# nrf7140_wificore register map
Vendor: Nordic Semiconductor; Series: nRF71; File version: 1
Registers are 32-bit, read-write, reset 0x0 unless marked. A register's access mark holds for its fields unless they carry their own. Offsets are from the block's base; [hi:lo] are bit positions; lines under a group give offsets from that group; 'fields as' and 'values as' point back to an identical list; <NAME> marks a mode.

## RPUPHY (part 1 of 8) — WIFICore RPU PHY peripherals
Base 0x48080000; alternate view of RPUMAC
0x7000 SCP group — Unspecified
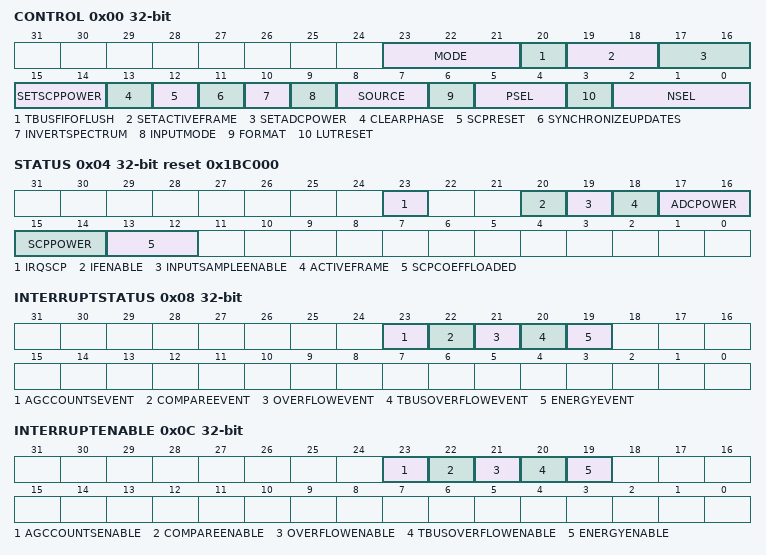
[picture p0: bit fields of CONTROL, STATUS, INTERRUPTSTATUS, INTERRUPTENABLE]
  0x00 CONTROL — SCP CONTROL
    [23:21] MODE — Defines the operating mode of the SCP as follows:0: Normal operation; SCP samples are output1: LO phase accumulator (MSB:MSB-11) is output on ILO phase accumulator(MSB-12:MSB-23) is output on Q2: Bypass mode 1; resampler results are output on I and Q3: Bypass mode 2; mixer results are output on I and Q4: Samples bypass the SCP completely
    [20] TBUSFIFOFLUSH — Writing '1' to this field causes the TBus output FIFO to be flushed.This bit clears automatically.
    [19:18] SETACTIVEFRAME
      0=NoChange; 1=NoChange1; 2=FrameAActive; 3=FrameBActive
    [17:16] SETADCPOWER
      0=NoChange; 1=LowPowerMode; 2=PowerOn; 3=PowerOff
    [15:14] SETSCPPOWER
      0=NoChange; 1=LowPowerMode; 2=PowerOn; 3=PowerOff
    [13] CLEARPHASE
      0=Resampler and LO phase accumulators run normally; 1=ResamplerAndLoPhaseA1 (Resampler and LO phase accumulators are forced to zero)
    [12] SCPRESET
      0=SCP signal path operates normally; 1=SCP signal path held in a reset state (clears CIC and notch phase accumulators)
    [11] SYNCHRONIZEUPDATES
      0=Updates to parameters take effect immediately; 1=Updates to parameters are synchronized to the APPLY_PARAMETERS sample count value
    [10] INVERTSPECTRUM — Note: The mixer design under normal operation inverts the output I and Q samples even if this field is set to 0. To re-invert set field to 1.
      0=The mixer output spectrum is not inverted; 1=TheMixerOutputSpectr1 (The mixer output spectrum is inverted by swapping I and Q)
    [9] INPUTMODE
      0=Input samples represent a real IF signal; 1=Input samples are I/Q pairs
    [8:7] SOURCE — Specifies the input IF sample source as follows:
      0=SourceIsOnBoardAdc; 1=SourceIsTbusWrPort; 2=SourceIsInputSample; 3=Reserve (This is reserved.)
    [6] FORMAT — Specifies the input IF sample format as follows:
      0=2SComplementSamples; 1=OffsetBinarySamples
    [5:4] PSEL — Defines the decimation ratio P of the final decimation stage of the SCP as follows:
      0=P2; 1=P3; 2=P1; 3=P4
    [3] LUTRESET — Writing '1' to this field causes the LUT select signals to be reset.This bit clears automatically.
    [2:0] NSEL — Defines the decimation ratio N of the first decimation stage of the SCP as follows:
      0=NoDecimation; 1=DecimateBy2; 2=DecimateBy3; 3=DecimateBy4; 4=DecimateBy6; 5=DecimateBy8; 6=DecimateBy12; 7=DecimateBy16
  0x04 STATUS ro reset 0x1BC000 — SCP STATUS
    [23] IRQSCP — This signal reflects the state of the IRQ_SCP interrupt.This interrupt is controlled by SCP_Interrupt_Enable.
    [20] IFENABLE
      0=Input synchroniser not enabled; 1=Input synchroniser enabled
    [19] INPUTSAMPLEENABLE
      0=SCP not ready for write to SCP_INPUT_SAMPLE register; 1=SCP ready for write to SCP_INPUT_SAMPLE register
    [18] ACTIVEFRAME
      0=FrameAActive; 1=FrameBActive
    [17:16] ADCPOWER
      0=Undefined; 1=LowPowerMode; 2=PowerOn; 3=PowerOff
    [15:14] SCPPOWER
      0=Undefined; 1=LowPowerMode; 2=PowerOn; 3=PowerOff
    [13:12] SCPCOEFFLOADED
      0=CoeffsAreNotLoaded; 2=CoeffsSet0IsLoaded; 3=CoeffsSet1IsLoaded
  0x08 INTERRUPTSTATUS — SCP INTERRUPT STATUS
    [23] AGCCOUNTSEVENT — This bit is set to 1 when the AGC period has completed.Writing 1 sets this bit for test purposes (and hence asserts the interrupt if AGC_COUNTS_ENABLE is also set).
    [22] COMPAREEVENT — This bit is set to 1 when the frame compare test has matched.Writing 1 sets this bit for test purposes (and hence asserts the interrupt if COMPARE_ENABLE is also set).
    [21] OVERFLOWEVENT — This bit is set to 1 when the input synchroniser has overflowed.Writing 1 sets this bit for test purposes (and hence asserts the interrupt if OVERFLOW_ENABLE is also set).
    [20] TBUSOVERFLOWEVENT — This bit is set to 1 if the TBus output FIFO overflows.Writing 1 sets this bit for test purposes (and hence asserts the interrupt if TBUS_OVERFLOW_ENABLE is also set).
    [19] ENERGYEVENT — This bit is set to 1 when Energy Monitor outputs are ready to be read.Writing 1 sets this bit for test purposes (and hence asserts the interrupt if ENERGY_ENABLE is also set).
  0x0C INTERRUPTENABLE — SCP INTERRUPT ENABLE
    [23] AGCCOUNTSENABLE — IRQ_SCP is asserted when AGC_COUNTS_EVENT=1 and AGC_COUNTS_ENABLE=1.
    [22] COMPAREENABLE — IRQ_SCP is asserted when COMPARE_EVENT=1 and COMPARE_ENABLE=1.
    [21] OVERFLOWENABLE — IRQ_SCP is asserted when OVERFLOW_EVENT=1 and OVERFLOW_ENABLE=1.
    [20] TBUSOVERFLOWENABLE — IRQ_SCP is asserted when TBUS_OVERFLOW_EVENT=1 and TBUS_OVERFLOW_ENABLE=1.
    [19] ENERGYENABLE — IRQ_SCP is asserted when ENERGY_EVENT=1 and ENERGY_ENABLE=1.
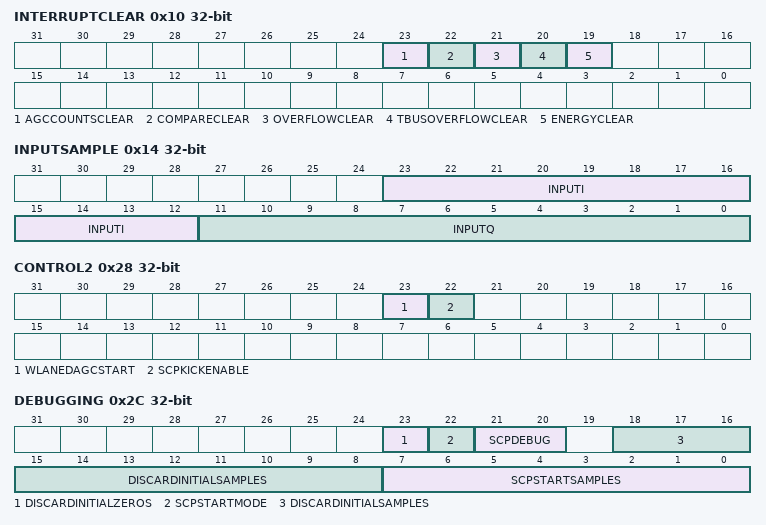
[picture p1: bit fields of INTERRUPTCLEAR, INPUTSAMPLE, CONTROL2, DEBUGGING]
  0x10 INTERRUPTCLEAR — SCP INTERRUPT CLEAR
    [23] AGCCOUNTSCLEAR — Writing 1 to this bit sets AGC_COUNTS_EVENT to 0.
    [22] COMPARECLEAR — Writing 1 to this bit sets COMPARE_EVENT to 0
    [21] OVERFLOWCLEAR — Writing 1 to this bit sets OVERFLOW_EVENT to 0
    [20] TBUSOVERFLOWCLEAR — Writing 1 to this bit sets TBUS_OVERFLOW_EVENT to 0
    [19] ENERGYCLEAR — Writing 1 to this bit sets ENERGY_EVENT to 0
  0x14 INPUTSAMPLE — SCP INPUT SAMPLE
    [23:12] INPUTI — For 12-bit SCP : write input sample I component.For 16-bit SCP : write input sample I[15:12] followed by Q[15:12].Poll for INPUT_SAMPLE_ENABLE=1 before writing.
    [11:0] INPUTQ — For 12-bit SCP : input sample Q component.For 16-bit SCP : write input sample I[11:0] followed by Q[11:0].Poll for INPUT_SAMPLE_ENABLE=1 before writing.
  0x18 REFERENCECLOCKCONTROLN — SCP REFERENCE CLOCK CONTROL N
    [23:8] N — The frequency of the output ref_clk is R x (N[14:0] / (M * 2)), where R is the SCP output sample frequency when N[15]=0, else the core clock frequency.If N and M are to be used to scale the reference clock M must be programmed first followed by N.Note that the reference clock control can only act as a divider not as a multiplier so the ratio (N[14:0] / (M * 2)) must be less than or equal to 0.5.
  0x1C REFERENCECLOCKCONTROLM — SCP REFERENCE CLOCK CONTROL M
    [23:8] M — The frequency of the output ref_clk is R x (N[14:0] / (M * 2)), where R is the SCP sample frequency when N[15]=0, else the core clock frequency.If N and M are to be used to scale the reference clock M must be programmed first followed by N.Note that the Reference clock control can only act as a divider not as a multiplier so the ratio (N[14:0] / (M * 2)) must be less than or equal to 0.5.
  0x20 CICBYPASS — SCP CIC BYPASS
    [23] CICBYPASS — Used to set the bypass mode of the CIC block.When bypass is set the CIC block is powered down and data passes around it unaltered.When cleared the block operates as programmed by the registers that control it.
      0=NormalOperation; 1=Block Bypassed (overrules any other block settings)
  0x24 RSSIINPUT — SCP RSSI INPUT
    [19:8] RSSIINPUT — RSSI (Received Signal Strength Indicator) ADC input captured on AGC sample period trigger
  0x28 CONTROL2 — SCP CONTROL2
    [23] WLANEDAGCSTART — Note: In mode 1 the input data rate to the SCP must be greater than or equal to the output data rate.
      0=SCP not used for processing Wi-Fi samples. No hold off provided to synchronize output samples with ADC input, DMA output enabled at start of frame.; 1=SCP used for processing Wi-Fi samples. Provides hold off to synchronize output samples with ADC input, DMA output enabled by agc_done signal from Wi-Fi AGC.
    [22] SCPKICKENABLE
      0=Writes to SET_ADC_POWER/SET_SCP_POWER/NEW_ADC_POWER/NEW_SCP_POWER/INPUT_I/INPUT_Q registers not deferred until kick received from EDC_SCP_KICK register to synchroniser update of these registers to multiple SCPs; 1=WritesToSetAdcPowe1 (Writes to SET_ADC_POWER/SET_SCP_POWER/NEW_ADC_POWER/NEW_SCP_POWER/INPUT_I/INPUT_Q registers deferred until kick received from EDC_SCP_KICK register to synchroniser update of these registers to multiple SCPs.)
  0x2C DEBUGGING — SCP DEBUG
    [23] DISCARDINITIALZEROS
      0=Process all ADC input samples; 1=Discard initial ADC input data until first non-zero sample
    [22] SCPSTARTMODE
      0=Output all SCP output samples, or all samples after ED event when WLAN_EDAGC_START=1; 1=Discard first SCP_START_SAMPLES SCP output samples
    [21:20] SCPDEBUG — Enable debug registers SCP_DEBUG_VALID and SCP_DEBUG_ENABLE
      0=Disabled; 1=ValidEnable; 2=Sticky(Valid), Sticky(Enable); 3=Valid & Enable, Sticky(Valid & Enable)
    [18:8] DISCARDINITIALSAMPLES — Number of initial ADC samples to discard
    [7:0] SCPSTARTSAMPLES — Number of samples before enabling SCP output when SCP_START_MODE=1
  0x30 DEBUGVALID0 ro — SCP DEBUG VALID 0
    [23:0] SCPDEBUGVALID0 — Live state of the valid flow control signals0: Source Synchroniser Output1: RI/Q Formatter Input2: RI/Q Formatter Output3: NDRM Decimator Input4: NDRM Decimator Output5: FDC Offset Input6: FDC Offset Output7: EEarly Gain Input8: EEarly Gain Output9: RMixer Input10: Mixer Output11: Resampler Input12: Resampler Output13: IQ Imbalance Input14: IQ Imbalance Output15: CIC Decimator Input16: CIC Decimator Output17: FIR Decimator Input18: FIR Decimator Output19: Notch Filter Input20: Notch Filter Output21: Late Gain Input22: Late Gain Output23: Impulse Filter Input
  0x34 DEBUGVALID1 ro — SCP DEBUG VALID 1
    [6:0] SCPDEBUGVALID1 — Live state of the valid flow control signals0: Impulse Filter Output1: Output Mux Input2: FIFO Write3: FIFO Output4: Unpacker Input5: EDC T-Bus Read Peripheral Input6: EDC T-Bus Read Peripheral Output
  0x38 DEBUGENABLE0 ro — SCP DEBUG ENABLE 0
    [23:0] SCPDEBUGENABLE0 — Live state of the valid flow control signals0: Source Synchroniser Output1: RI/Q Formatter Input2: RI/Q Formatter Output3: NDRM Decimator Input4: NDRM Decimator Output5: FDC Offset Input6: FDC Offset Output7: EEarly Gain Input8: EEarly Gain Output9: RMixer Input10: Mixer Output11: Resampler Input12: Resampler Output13: IQ Imbalance Input14: IQ Imbalance Output15: CIC Decimator Input16: CIC Decimator Output17: FIR Decimator Input18: FIR Decimator Output19: Notch Filter Input20: Notch Filter Output21: Late Gain Input22: Late Gain Output23: Impulse Filter Input
  0x3C DEBUGENABLE1 ro — SCP DEBUG ENABLE 1
    [6:0] SCPDEBUGENABLE1 — Live state of the valid flow control signals0: Impulse Filter Output1: Output Mux Input2: FIFO Full3: FIFO Output4: Unpacker Input5: EDC T-Bus Read Peripheral Input6: EDC T-Bus Read Peripheral Output
  0x40 COEFFADDR — SCP COEFF ADDR
    [5:0] SCPCOEFFADDR — Address for coefficient of final (FIR) decimation filter.NOTE: use FIR_COEFF_SET_SEL to select the coefficients set.
  0x44 COEFFDATA — SCP COEFF DATA
    [16:0] SCPCOEFFDATA — Data for coefficient of final (FIR) decimation filter in 2's complement format where the range of numbers represented is -1.0 to 1.0.SCP_COEFF_ADDR automatically increments following write.
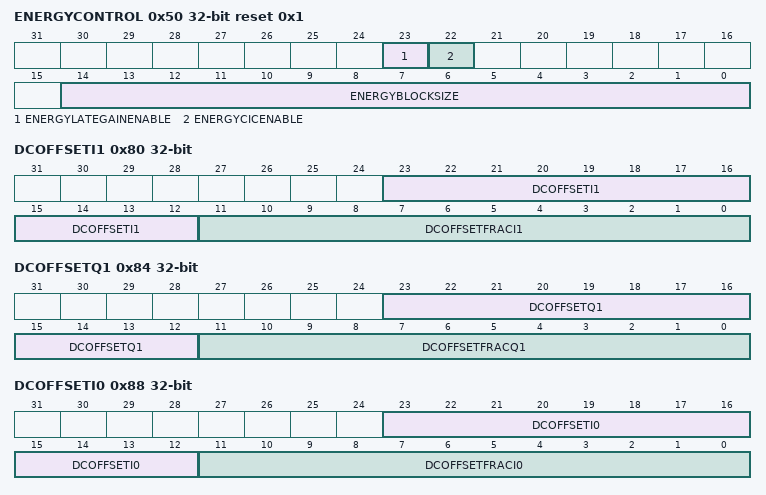
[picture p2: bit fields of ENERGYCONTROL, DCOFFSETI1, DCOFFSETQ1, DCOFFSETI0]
  0x50 ENERGYCONTROL reset 0x1 — SCP ENERGY CONTROL
    [23] ENERGYLATEGAINENABLE — Enable control for the energy calculation on the input of the late gain block:
      0=Energy calculation disabled; 1=Energy calculation enabled
    [22] ENERGYCICENABLE — Enable, disable the energy calculation on the input of the CIC decimator block.
      0=Energy calculation disabled; 1=Energy calculation enabled
    [14:0] ENERGYBLOCKSIZE — Block size for the energy calculation at the CIC decimator and the late gain stage, shifted right by 6.Takes values in the range [1 ~ 2^14] and must be a power of 2.
  0x54 ENERGYCICVALUE ro — SCP ENERGY CIC VALUE
    [23:0] ENERGYCICVALUE — Energy value from CIC decimator energy monitor block.
  0x58 ENERGYLATEGAINVALUE ro — SCP ENERGY LATE GAIN VALUE
    [23:0] ENERGYLATEGAINVALUE — Energy value from late gain energy monitor block.
  0x60 EARLYCOARSEGAIN — SCP EARLY COARSE GAIN
    [23:22] EARLYCOARSEGAIN — Coarse gain applied in the early gain block.
      0=CoarseGainOf1; 1=CoarseGainOf14; 2=CoarseGainOf4; 3=Reserve (This is reserved.)
  0x64 EARLYFINEGAINI reset 0x200000 — SCP EARLY FINE GAIN I
    [23:10] EARLYIGAIN — 2's complement value that multiplies I value from SCP.This is a linear gain where 0x800 represents the 0dB point, thus the fine gain is EARLY_I_GAIN/0x800.Bits 23:13 valid for 12-bit SCP, bits 23:10 valid for 16-bit SCP.
  0x68 EARLYFINEGAINQ reset 0x200000 — SCP EARLY FINE GAIN Q
    [23:10] EARLYQGAIN — 2's complement value that multiplies Q value from SCP.This is a linear gain where 0x800 represents the 0dB point, thus the fine gain is EARLY_Q_GAIN/0x800.Bits 23:13 valid for 12-bit SCP, bits 23:10 valid for 16-bit SCP.
  0x6C EARLYANGLEIQ — SCP EARLY ANGLE IQ
    [23:10] EARLYITOQGAIN — 2's complement value that multiplies I value before addition to Q value in the early gain block.Qout = Q + (I * EARLY_I_TO_Q_GAIN >> 13).Bits 23:13 valid for 12-bit SCP, bits 23:10 valid for 16-bit SCP.
  0x74 LATECOARSEGAIN — SCP LATE COARSE GAIN
    [23] LATECOARSEGAIN — Coarse gain applied in the late gain block.
      0=CoarseGainOf1; 1=CoarseGainOf4
  0x78 LATEFINEGAINI reset 0x200000 — SCP LATE FINE GAIN I
    [23:13] LATEIGAIN — 2's complement value that multiplies I value from SCP. This is a linear gain where 0x100 represents the 0dB point, thus the fine gain is LATE_I_GAIN/0x100.
  0x7C LATEFINEGAINQ reset 0x200000 — SCP LATE FINE GAIN Q
    [23:13] LATEQGAIN — 2's complement value that multiplies Q value from SCP. This is a linear gain where 0x100 represents the 0dB point, thus the fine gain is LATE_Q_GAIN/0x100.
  0x80 DCOFFSETI1 — SCP DC OFFSET I 1
    [23:12] DCOFFSETI1 — DC offset cancellation value for the real or I channel. 2's complement value, where the number of integer bits are defined by the I channel size and the remainder bits are fractional. The fractional bits enter a wrapping accumulator and the carry from this is summed with the integer offset.
    [11:0] DCOFFSETFRACI1 — DC offset cancellation value for the real or I channel. 2's complement value, where the number of integer bits are defined by the I channel size and the remainder bits are fractional. The fractional bits enter a wrapping accumulator and the carry from this is summed with the integer offset.
  0x84 DCOFFSETQ1 — SCP DC OFFSET Q 1
    [23:12] DCOFFSETQ1 — DC offset cancellation value for the Q channel. 2's complement value, where the number of integer bits are defined by the Q channel size and the remainder bits are fractional. The fractional bits enter a wrapping accumulator and the carry from this is summed with the integer offset.
    [11:0] DCOFFSETFRACQ1 — DC offset cancellation value for the Q channel. 2's complement value, where the number of integer bits are defined by the Q channel size and the remainder bits are fractional. The fractional bits enter a wrapping accumulator and the carry from this is summed with the integer offset.
  0x88 DCOFFSETI0 — SCP DC OFFSET I 0
    [23:12] DCOFFSETI0 — DC offset cancellation value for the real or I channel. 2's complement value, where the number of integer bits are defined by the I channel size and the remainder bits are fractional. The fractional bits enter a wrapping accumulator and the carry from this is summed with the integer offset.
    [11:0] DCOFFSETFRACI0 — DC offset cancellation value for the real or I channel. 2's complement value, where the number of integer bits are defined by the I channel size and the remainder bits are fractional. The fractional bits enter a wrapping accumulator and the carry from this is summed with the integer offset.
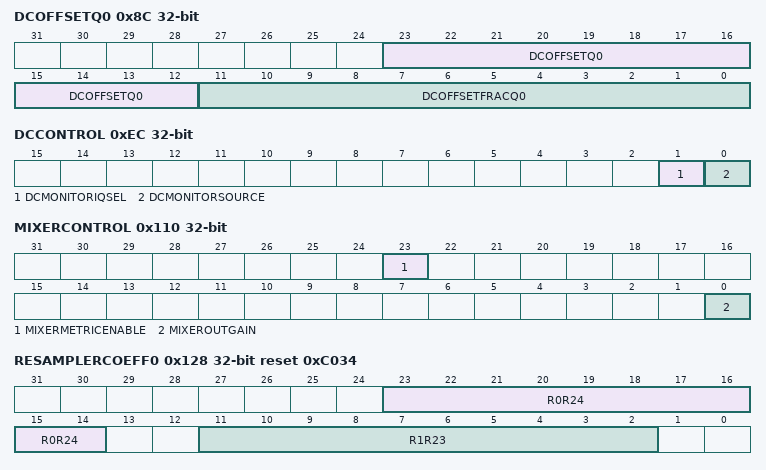
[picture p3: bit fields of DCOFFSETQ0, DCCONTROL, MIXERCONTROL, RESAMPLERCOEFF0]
  0x8C DCOFFSETQ0 — SCP DC OFFSET Q 0
    [23:12] DCOFFSETQ0 — DC offset cancellation value for the Q channel. 2's complement value, where the number of integer bits are defined by the Q channel size and the remainder bits are fractional. The fractional bits enter a wrapping accumulator and the carry from this is summed with the integer offset.
    [11:0] DCOFFSETFRACQ0 — DC offset cancellation value for the Q channel. 2's complement value, where the number of integer bits are defined by the Q channel size and the remainder bits are fractional. The fractional bits enter a wrapping accumulator and the carry from this is summed with the integer offset.
  0x90 EXTGAINCONTROL1 — SCP EXT GAIN CONTROL 1
    [23:12] GAINCONTROL1 — External gain control signal for channel 1 (I channel)
  0x94 EXTGAINCONTROL2 — SCP EXT GAIN CONTROL 2
    [23:12] GAINCONTROL2 — External gain control signal for channel 2 (Q Channel)
  0x98 EXTOFFSETCONTROL1 — SCP EXT OFFSET CONTROL 1
    [23:12] OFFSETCONTROL1 — External offset control signal for channel 1 (I Channel)
  0x9C EXTOFFSETCONTROL2 — SCP EXT OFFSET CONTROL 2
    [23:12] OFFSETCONTROL2 — External offset control signal for channel 2 (Q Channel)
  0xA0 EARLYGAINBYPASS — SCP EARLY GAIN BYPASS
    [23] EARLYBYPASS — Used to set the bypass mode of the Early Gain block.When bypass is set the Early Gain block is powered down and data passes around it unaltered.When set to Normal the block operates as programmed by the registers that control it.
      values as SCP.CICBYPASS.CICBYPASS
  0xA4 LATEGAINBYPASS — SCP LATE GAIN BYPASS
    [23] LATEBYPASS — Used to set the bypass mode of the Late Gain block.When bypass is set the Late Gain block is powered down and data passes around it unaltered.When set to Normal the block operates as programmed by the registers that control it.
      values as SCP.CICBYPASS.CICBYPASS
  0xB0 IQCORRCONTROL — SCP IQCORR CONTROL
    [23] IQCORRENABLE — Used to enable the IQ Correlator for detecting angle error on a Zero-IF input signal
      0=IQ Correlator is disabled; 1=IQ Correlator is enabled)
  0xB4 IQCORRSTATUS ro — SCP IQCORR STATUS
    [20:0] IQCORROUT — IQ Correlator output for detecting angle error on a Zero-IF input signal.This value is latched and held when the IRQ_SCP interrupt is asserted due to AGC_COUNTS_EVENT.
  0xB8 AGCNOISEPERIOD — SCP AGC NOISE PERIOD
    [23:5] NOISEPERIOD — Period of the input sample counter - 1e.g. 0 gives period of sample length 1, 1 gives period of sample length 2, 2 gives period of sample length 3.The value has to be already adjusted according to DRM decimation factor, resampling rate and CIC & FIR decimation factors.NOISE_PERIOD = ((AGC_PERIOD / (((RESAMP_BASE * 2^23) + RESAMP_CONTROL) / 2^25)) / P) / N.
  0xC0 AGCCLIPCONTROL — SCP AGC CLIP CONTROL
    [18:4] AGCCLIP — Threshold value against which the absolute value of IF samples is compared in the logic that generates CLIP_COUNT.Bits 18:8 valid for 12-bit SCP, bits 18:4 valid for 16-bit SCP.
  0xC4 AGCTHRESHCONTROL — SCP AGC THRESH CONTROL
    [18:4] AGCTHRESH — Threshold value against which the absolute value of IF samples is compared in the logic that generates THRESH_COUNT.Bits 18:8 valid for 12-bit SCP, bits 18:4 valid for 16-bit SCP.
  0xC8 AGCPERIOD — SCP AGC PERIOD
    [23:6] AGCPERIOD — Period of the input sample counter - 1e.g. 0 gives period of sample length 1, 1 gives period of sample length 2, 2 gives period of sample length 3.The value has to be already adjusted according to DRM decimation factor.
  0xCC AGCSAMPLECOUNTER ro — SCP AGC SAMPLE COUNTER
    [23:6] AGCCOUNT — Current value of the AGC sample counter. This counts pairs of input samples (I and Q).
  0xD0 AGCCLIPCOUNTI ro — SCP AGC CLIP COUNT I
    [23:6] CLIPCOUNTI — The number of IF samples at either extreme of the ADC range (greater than AGC_CLIP) recorded during the last complete AGC_PERIOD of the I sample stream.This value is latched and held when the IRQ_SCP interrupt is asserted due to AGC_COUNTS_EVENT.
  0xD4 AGCTHRESHCOUNTI ro — SCP AGC THRESH COUNT I
    [23:6] THRESHCOUNTI — The number of IF samples with absolute value greater than AGC_THRESH recorded during the last complete AGC_PERIOD of the I sample stream.This value is latched and held when the IRQ_SCP interrupt is asserted due to AGC_COUNTS_EVENT.
  0xD8 AGCCLIPCOUNTQ ro — SCP AGC CLIP COUNT Q
    [23:6] CLIPCOUNTQ — The number of IF samples at either extreme of the ADC range (greater than AGC_CLIP) recorded during the last complete AGC_PERIOD of the Q sample stream.This value is latched and held when the IRQ_SCP interrupt is asserted due to AGC_COUNTS_EVENT.
  0xDC AGCTHRESHCOUNTQ ro — SCP AGC THRESH COUNT Q
    [23:6] THRESHCOUNTQ — The number of IF samples with absolute value greater than AGC_THRESH recorded during the last complete AGC_PERIOD of the Q sample stream.This value is latched and held when the IRQ_SCP interrupt is asserted due to AGC_COUNTS_EVENT.
  0xE0 DCMONITORI ro — SCP DC MONITOR I
    [23:0] DCMONITORI — Measures the DC component of the I signal from the ADC to allow feedback to the RF to reduce the long-term DC offset to zero.This value is latched and held when the IRQ_SCP interrupt is asserted due to AGC_COUNTS_EVENT.
  0xE4 DCMONITORQ ro — SCP DC MONITOR Q
    [23:0] DCMONITORQ — Measures the DC component of the Q signal from the ADC to allow feedback to the RF to reduce the long-term DC offset to zero.This value is latched and held when the IRQ_SCP interrupt is asserted due to AGC_COUNTS_EVENT.
  0xE8 DCBYPASS — SCP DC BYPASS
    [23] DCBYPASS — Used to set the bypass mode of the DC Offset block.When bypass is set the DC Offset block is powered down and data passes around it unaltered.When set to Normal the block operates as programmed by the registers that control it.
      values as SCP.CICBYPASS.CICBYPASS
  0xEC DCCONTROL — SCP DC CONTROL
    [1] DCMONITORIQSEL — Selects which part of the 32 bit register hoding the dc_monitor_i/q value is read out from the DC_MONITOR_I/Q field of the register SCP_DC_MONITOR_I/Q.0 : Lower 16 bits are read out from the DC_MONITOR_I/Q[15:0] field.1 : Upper 16 bits are read out from the DC_MONITOR_I/Q[15:0] field.Only valid for 16-bit SCP, unused by 12-bit SCP.
    [0] DCMONITORSOURCE — Selects the source for input to the DC Monitor:
      0=The output of the DRM Decimator (default); 1=The output of the DC Offset Control
  0x100 LOBASE — SCP LO BASE
    [23:21] LOBASE — Local Oscillator base. This is an unsigned value which is combined with LO_CONTROL to generate the 26-bit control Fc:Fc = (LO_BASE << 23) + LO_CONTROLFc is in 2's complement signed format where its value represents numbers within the range -1 to 0.9999999. To convert a ratio into the 26-bit Fc, multiply by 2^25.The digitally generated Local Oscillator (LO) frequency used in the mixer section is equal to Fc * (IF Clock Frequency/2). Hence the full-scale negative value represents a frequency of -(IF Clock Frequency/2).The input signal is frequency translated such that input frequency F moves to a frequency of F + Local Oscillator (LO) Frequency.NOTE : a real IF input implicitly carries the inverse of its positive spectrum at negative frequencies. This means that a positive Fc applied to a real IF gives an inverted spectrum, and a negative Fc gives a non-inverted one. An SCP input contains independent positive and negative frequency components, so Fc cannot invert the spectrum.
  0x104 LOCONTROL — SCP LO CONTROL
    [23:0] LOCONTROL — Local Oscillator control. This is a 2's complement value which is combined with LO_BASE to generate the 26-bit control Fc:Fc = (LO_BASE << 23) + LO_CONTROL
  0x10C MIXERBYPASS — SCP MIXER BYPASS
    [23] MIXERBYPASS — Used to set the bypass mode of the Mixer block.When bypass is set the Mixer block is powered down and data passes around it unaltered.When set to Normal the block operates as programmed by the registers that control it.
      values as SCP.CICBYPASS.CICBYPASS
  0x110 MIXERCONTROL — SCP MIXER CONTROL
    [23] MIXERMETRICENABLE — Used to enable the Mixer IQ level imbalance estimation metric generation:
      0=Mixer IQ metric is disabled; 1=Mixer IQ metric is enabled)
    [0] MIXEROUTGAIN — Selects Mixer output gain:NOTE: Using a setting of 2.0 increases the signal strength by 6 dB as both real & imaginary components are scaled.
      0=Gain of 1.0 is applied to the output of Mixer rotator (default); 1=Gain of 2.0 is applied to the output of Mixer rotator (used to compensate for 0.5 gain in real input mode)
  0x114 MIXERMETRICSTATUS ro
    [21:0] MIXERMETRICOUT — Mixer IQ level imbalance estimation metric accumulated over AGC period.
  0x120 RESAMPLINGFACTORBASE reset 0x800000 — SCP RESAMPLING FACTOR BASE
    [23:21] RESAMPBASE — Resampling factor base. This is an unsigned value which is combined with the 2's complement RESAMP_CONTROL to generate the 26-bit control Fs:Fs = (RESAMP_BASE << 23) + RESAMP_CONTROLFs is the sample conversion ratio (I / O) used in the sample rate conversion section of the SCP.Fs is an unsigned number, where the full-scale range of values is 1 / (2^25) to ((2^26) - 1) / (2^25) = 2.98023224E-08 to 1.99999997NOTE: To convert a ratio into the 26-bit Fs, multiply by 2^25
  0x124 RESAMPLINGFACTORCONTROL — SCP RESAMPLING FACTOR CONTROL
    [23:0] RESAMPCONTROL — Resampling factor control. This is a 2's complement value which is combined with RESAMP_BASE to generate the 26-bit control Fs:Fs = (RESAMP_BASE << 23) + RESAMP_CONTROL
  0x128 RESAMPLERCOEFF0 reset 0xC034 — SCP RESAMPLERCOEFF 0
    [23:14] R0R24 — Coefficient of resampler filter in 2's complement format.Only valid for 12-bit SCP, SCP_RESAMPLERCOEFF_ADDR/DATA must be used for 16-bit SCP.
    [11:2] R1R23 — Coefficient of resampler filter in 2's complement format.Only valid for 12-bit SCP, SCP_RESAMPLERCOEFF_ADDR/DATA must be used for 16-bit SCP.
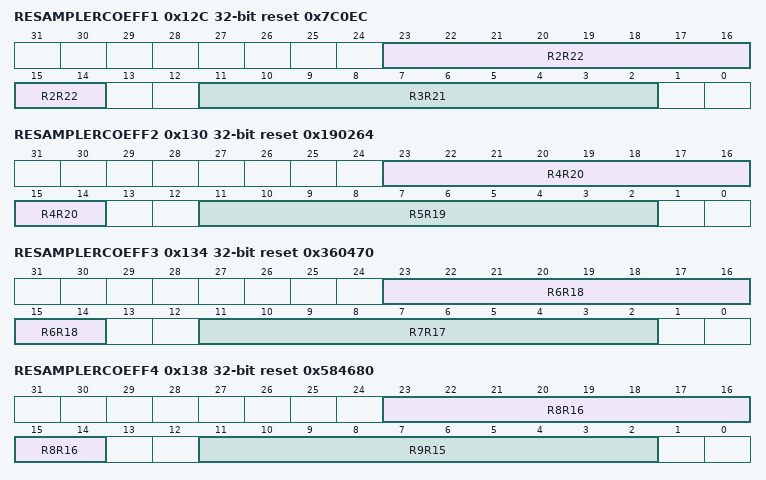
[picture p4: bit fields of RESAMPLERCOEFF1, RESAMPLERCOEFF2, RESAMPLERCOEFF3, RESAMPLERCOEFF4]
  0x12C RESAMPLERCOEFF1 reset 0x7C0EC — SCP RESAMPLERCOEFF 1
    [23:14] R2R22 — Coefficient of resampler filter in 2's complement format.Only valid for 12-bit SCP, SCP_RESAMPLERCOEFF_ADDR/DATA must be used for 16-bit SCP.
    [11:2] R3R21 — Coefficient of resampler filter in 2's complement format.Only valid for 12-bit SCP, SCP_RESAMPLERCOEFF_ADDR/DATA must be used for 16-bit SCP.
  0x130 RESAMPLERCOEFF2 reset 0x190264 — SCP RESAMPLERCOEFF 2
    [23:14] R4R20 — Coefficient of resampler filter in 2's complement format.Only valid for 12-bit SCP, SCP_RESAMPLERCOEFF_ADDR/DATA must be used for 16-bit SCP.
    [11:2] R5R19 — Coefficient of resampler filter in 2's complement format.Only valid for 12-bit SCP, SCP_RESAMPLERCOEFF_ADDR/DATA must be used for 16-bit SCP.
  0x134 RESAMPLERCOEFF3 reset 0x360470 — SCP RESAMPLERCOEFF 3
    [23:14] R6R18 — Coefficient of resampler filter in 2's complement format.Only valid for 12-bit SCP, SCP_RESAMPLERCOEFF_ADDR/DATA must be used for 16-bit SCP.
    [11:2] R7R17 — Coefficient of resampler filter in 2's complement format.Only valid for 12-bit SCP, SCP_RESAMPLERCOEFF_ADDR/DATA must be used for 16-bit SCP.
  0x138 RESAMPLERCOEFF4 reset 0x584680 — SCP RESAMPLERCOEFF 4
    [23:14] R8R16 — Coefficient of resampler filter in 2's complement format.Only valid for 12-bit SCP, SCP_RESAMPLERCOEFF_ADDR/DATA must be used for 16-bit SCP.
    [11:2] R9R15 — Coefficient of resampler filter in 2's complement format.Only valid for 12-bit SCP, SCP_RESAMPLERCOEFF_ADDR/DATA must be used for 16-bit SCP.
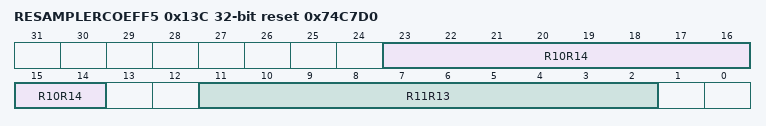
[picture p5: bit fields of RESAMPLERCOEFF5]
  0x13C RESAMPLERCOEFF5 reset 0x74C7D0 — SCP RESAMPLERCOEFF 5
    [23:14] R10R14 — Coefficient of resampler filter in 2's complement format.Only valid for 12-bit SCP, SCP_RESAMPLERCOEFF_ADDR/DATA must be used for 16-bit SCP.
    [11:2] R11R13 — Coefficient of resampler filter in 2's complement format.Only valid for 12-bit SCP, SCP_RESAMPLERCOEFF_ADDR/DATA must be used for 16-bit SCP.
  0x140 RESAMPLERCOEFF6 reset 0x7FC000 — SCP RESAMPLERCOEFF 6
    [23:14] R12 — Coefficient of resampler filter in 2's complement format.Only valid for 12-bit SCP, SCP_RESAMPLERCOEFF_ADDR/DATA must be used for 16-bit SCP.
  0x144 RESAMPLERBYPASS — SCP RESAMPLER BYPASS
    [23] RESAMPBYPASS — Used to set the bypass mode of the Resampler block.When bypass is set the Resampler block is powered down and data passes around it unaltered.When set to Normal the block operates as programmed by the registers that control it.
      values as SCP.CICBYPASS.CICBYPASS
  0x148 RESAMPLERCONTROL reset 0x1 — SCP RESAMPLER CONTROL
    [1:0] RESAMPOUTGAIN — Selects Resampler output gain to normalise the gain range (0.65 to 3.9):
      0=Gain of 0.25 (>>11) is applied to the output of Resampler; 1=Gain of 0.5(>>10) is applied to the output of Resampler (default); 2=Gain of 1.0 (>>9) is applied to the output of Resampler; 3=Gain of 2.0 (>>8) is applied to the output of Resampler
